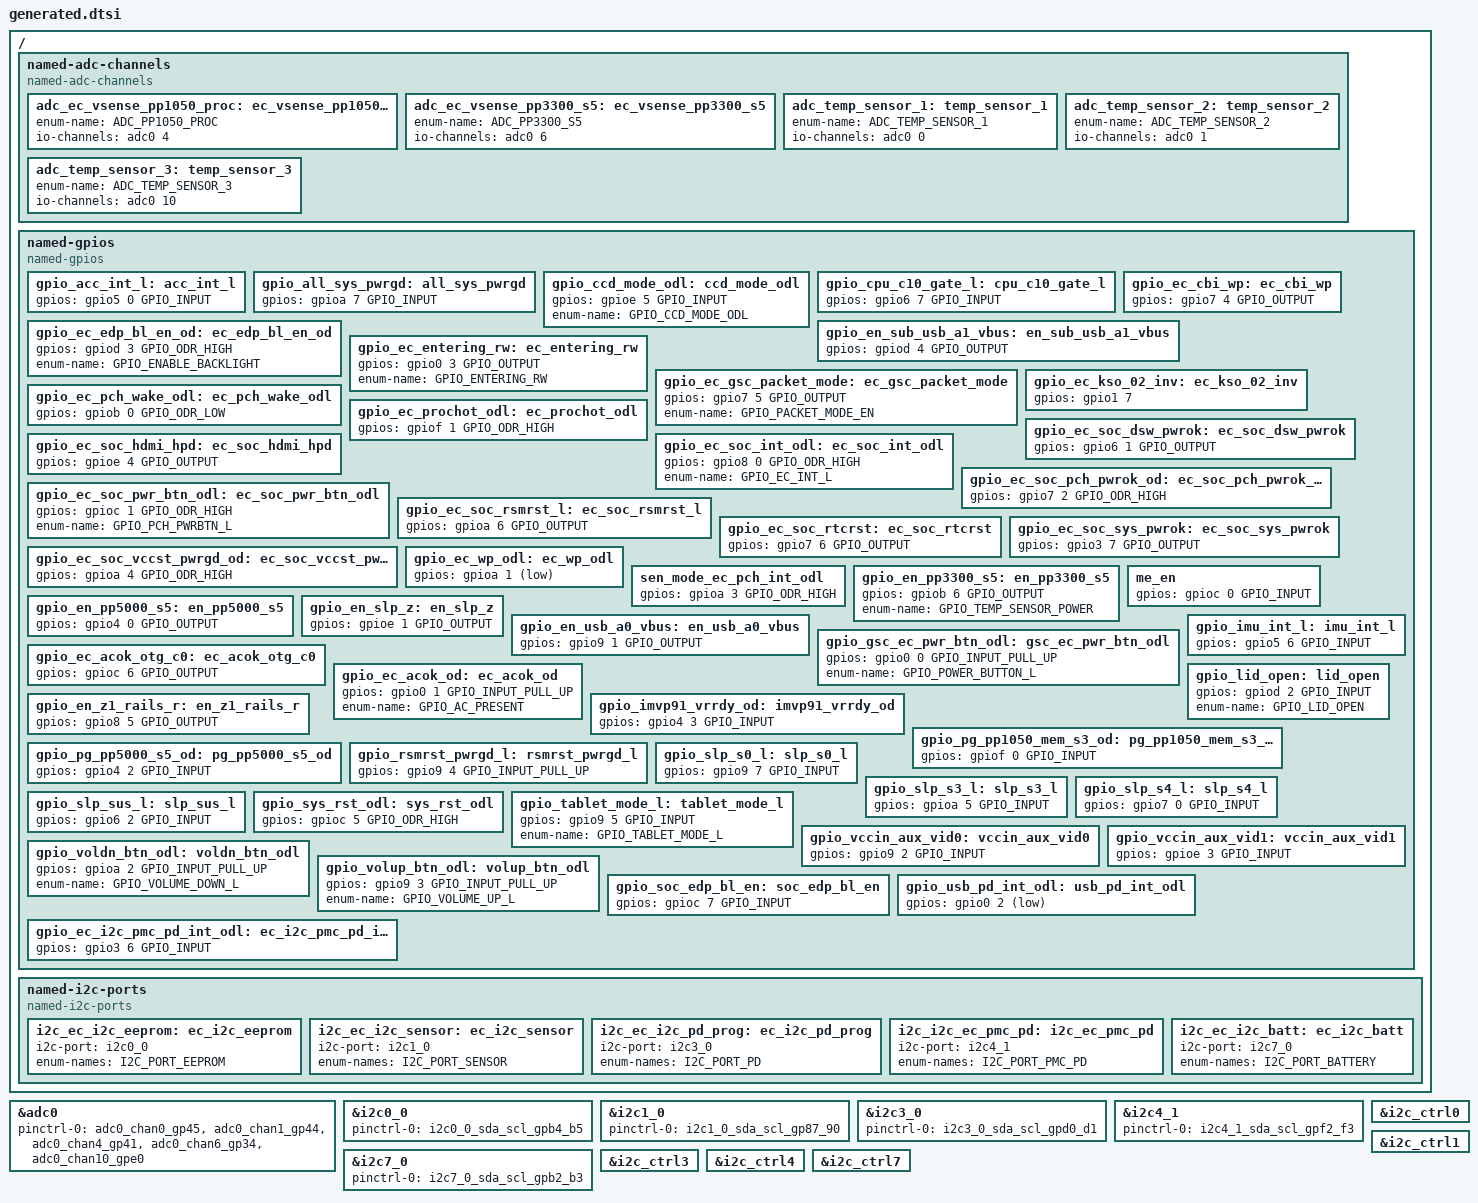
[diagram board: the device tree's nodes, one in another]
/* Copyright 2022 The ChromiumOS Authors
 * Use of this source code is governed by a BSD-style license that can be
 * found in the LICENSE file.
 *
 * This file is auto-generated - do not edit!
 */

/ {

	named-adc-channels {
		compatible = "named-adc-channels";

		adc_ec_vsense_pp1050_proc: ec_vsense_pp1050_proc {
			enum-name = "ADC_PP1050_PROC";
			io-channels = <&adc0 4>;
		};
		adc_ec_vsense_pp3300_s5: ec_vsense_pp3300_s5 {
			enum-name = "ADC_PP3300_S5";
			io-channels = <&adc0 6>;
		};
		adc_temp_sensor_1: temp_sensor_1 {
			enum-name = "ADC_TEMP_SENSOR_1";
			io-channels = <&adc0 0>;
		};
		adc_temp_sensor_2: temp_sensor_2 {
			enum-name = "ADC_TEMP_SENSOR_2";
			io-channels = <&adc0 1>;
		};
		adc_temp_sensor_3: temp_sensor_3 {
			enum-name = "ADC_TEMP_SENSOR_3";
			io-channels = <&adc0 10>;
		};
	};

	named-gpios {
		compatible = "named-gpios";

		gpio_acc_int_l: acc_int_l {
			gpios = <&gpio5 0 GPIO_INPUT>;
		};
		gpio_all_sys_pwrgd: all_sys_pwrgd {
			gpios = <&gpioa 7 GPIO_INPUT>;
		};
		gpio_ccd_mode_odl: ccd_mode_odl {
			gpios = <&gpioe 5 GPIO_INPUT>;
			enum-name = "GPIO_CCD_MODE_ODL";
		};
		gpio_cpu_c10_gate_l: cpu_c10_gate_l {
			gpios = <&gpio6 7 GPIO_INPUT>;
		};
		gpio_ec_cbi_wp: ec_cbi_wp {
			gpios = <&gpio7 4 GPIO_OUTPUT>;
		};
		gpio_ec_edp_bl_en_od: ec_edp_bl_en_od {
			gpios = <&gpiod 3 GPIO_ODR_HIGH>;
			enum-name = "GPIO_ENABLE_BACKLIGHT";
		};
		gpio_en_sub_usb_a1_vbus: en_sub_usb_a1_vbus {
			gpios = <&gpiod 4 GPIO_OUTPUT>;
		};
		gpio_ec_entering_rw: ec_entering_rw {
			/* test point */
			gpios = <&gpio0 3 GPIO_OUTPUT>;
			enum-name = "GPIO_ENTERING_RW";
		};
		gpio_ec_gsc_packet_mode: ec_gsc_packet_mode {
			gpios = <&gpio7 5 GPIO_OUTPUT>;
			enum-name = "GPIO_PACKET_MODE_EN";
		};
		gpio_ec_kso_02_inv: ec_kso_02_inv {
			gpios = <&gpio1 7 (GPIO_OUTPUT | GPIO_ACTIVE_HIGH)>;
		};
		gpio_ec_pch_wake_odl: ec_pch_wake_odl {
			gpios = <&gpiob 0 GPIO_ODR_LOW>;
		};
		gpio_ec_prochot_odl: ec_prochot_odl {
			gpios = <&gpiof 1 GPIO_ODR_HIGH>;
		};
		gpio_ec_soc_dsw_pwrok: ec_soc_dsw_pwrok {
			gpios = <&gpio6 1 GPIO_OUTPUT>;
		};
		gpio_ec_soc_hdmi_hpd: ec_soc_hdmi_hpd {
			gpios = <&gpioe 4 GPIO_OUTPUT>;
		};
		gpio_ec_soc_int_odl: ec_soc_int_odl {
			gpios = <&gpio8 0 GPIO_ODR_HIGH>;
			enum-name = "GPIO_EC_INT_L";
		};
		gpio_ec_soc_pch_pwrok_od: ec_soc_pch_pwrok_od {
			gpios = <&gpio7 2 GPIO_ODR_HIGH>;
		};
		gpio_ec_soc_pwr_btn_odl: ec_soc_pwr_btn_odl {
			gpios = <&gpioc 1 GPIO_ODR_HIGH>;
			enum-name = "GPIO_PCH_PWRBTN_L";
		};
		gpio_ec_soc_rsmrst_l: ec_soc_rsmrst_l {
			gpios = <&gpioa 6 GPIO_OUTPUT>;
		};
		gpio_ec_soc_rtcrst: ec_soc_rtcrst {
			gpios = <&gpio7 6 GPIO_OUTPUT>;
		};
		gpio_ec_soc_sys_pwrok: ec_soc_sys_pwrok {
			gpios = <&gpio3 7 GPIO_OUTPUT>;
		};
		gpio_ec_soc_vccst_pwrgd_od: ec_soc_vccst_pwrgd_od {
			gpios = <&gpioa 4 GPIO_ODR_HIGH>;
		};
		gpio_ec_wp_odl: ec_wp_odl {
			gpios = <&gpioa 1 (GPIO_INPUT | GPIO_ACTIVE_LOW)>;
		};
		sen_mode_ec_pch_int_odl {
			gpios = <&gpioa 3 GPIO_ODR_HIGH>;
		};
		gpio_en_pp3300_s5: en_pp3300_s5 {
			gpios = <&gpiob 6 GPIO_OUTPUT>;
			enum-name = "GPIO_TEMP_SENSOR_POWER";
		};
		me_en {
			/* workaround for b/333336079, reserved */
			gpios = <&gpioc 0 GPIO_INPUT>;
		};
		gpio_en_pp5000_s5: en_pp5000_s5 {
			gpios = <&gpio4 0 GPIO_OUTPUT>;
		};
		gpio_en_slp_z: en_slp_z {
			gpios = <&gpioe 1 GPIO_OUTPUT>;
		};
		gpio_en_usb_a0_vbus: en_usb_a0_vbus {
			gpios = <&gpio9 1 GPIO_OUTPUT>;
		};
		gpio_gsc_ec_pwr_btn_odl: gsc_ec_pwr_btn_odl {
			gpios = <&gpio0 0 GPIO_INPUT_PULL_UP>;
			enum-name = "GPIO_POWER_BUTTON_L";
		};
		gpio_ec_acok_otg_c0: ec_acok_otg_c0 {
			gpios = <&gpioc 6 GPIO_OUTPUT>;
		};
		gpio_imu_int_l: imu_int_l {
			gpios = <&gpio5 6 GPIO_INPUT>;
		};
		gpio_ec_acok_od: ec_acok_od {
			gpios = <&gpio0 1 GPIO_INPUT_PULL_UP>;
			enum-name = "GPIO_AC_PRESENT";
		};
		gpio_imvp91_vrrdy_od: imvp91_vrrdy_od {
			gpios = <&gpio4 3 GPIO_INPUT>;
		};
		gpio_lid_open: lid_open {
			gpios = <&gpiod 2 GPIO_INPUT>;
			enum-name = "GPIO_LID_OPEN";
		};
		gpio_en_z1_rails_r: en_z1_rails_r {
			gpios = <&gpio8 5 GPIO_OUTPUT>;
		};
		gpio_pg_pp1050_mem_s3_od: pg_pp1050_mem_s3_od {
			gpios = <&gpiof 0 GPIO_INPUT>;
		};
		gpio_pg_pp5000_s5_od: pg_pp5000_s5_od {
			gpios = <&gpio4 2 GPIO_INPUT>;
		};
		gpio_rsmrst_pwrgd_l: rsmrst_pwrgd_l {
			gpios = <&gpio9 4 GPIO_INPUT_PULL_UP>;
		};
		gpio_slp_s0_l: slp_s0_l {
			gpios = <&gpio9 7 GPIO_INPUT>;
		};
		gpio_slp_s3_l: slp_s3_l {
			gpios = <&gpioa 5 GPIO_INPUT>;
		};
		gpio_slp_s4_l: slp_s4_l {
			gpios = <&gpio7 0 GPIO_INPUT>;
		};
		gpio_slp_sus_l: slp_sus_l {
			gpios = <&gpio6 2 GPIO_INPUT>;
		};
		gpio_sys_rst_odl: sys_rst_odl {
			gpios = <&gpioc 5 GPIO_ODR_HIGH>;
		};
		gpio_tablet_mode_l: tablet_mode_l {
			gpios = <&gpio9 5 GPIO_INPUT>;
			enum-name = "GPIO_TABLET_MODE_L";
		};
		gpio_vccin_aux_vid0: vccin_aux_vid0 {
			gpios = <&gpio9 2 GPIO_INPUT>;
		};
		gpio_vccin_aux_vid1: vccin_aux_vid1 {
			gpios = <&gpioe 3 GPIO_INPUT>;
		};
		gpio_voldn_btn_odl: voldn_btn_odl {
			gpios = <&gpioa 2 GPIO_INPUT_PULL_UP>;
			enum-name = "GPIO_VOLUME_DOWN_L";
		};
		gpio_volup_btn_odl: volup_btn_odl {
			gpios = <&gpio9 3 GPIO_INPUT_PULL_UP>;
			enum-name = "GPIO_VOLUME_UP_L";
		};
		gpio_soc_edp_bl_en: soc_edp_bl_en {
			gpios = <&gpioc 7 GPIO_INPUT>;
		};
		gpio_usb_pd_int_odl: usb_pd_int_odl {
			gpios = <&gpio0 2 (GPIO_INPUT | GPIO_ACTIVE_LOW)>;
		};
		gpio_ec_i2c_pmc_pd_int_odl: ec_i2c_pmc_pd_int_odl {
			gpios = <&gpio3 6 GPIO_INPUT>;
		};
	};

	named-i2c-ports {
		compatible = "named-i2c-ports";

		i2c_ec_i2c_eeprom: ec_i2c_eeprom {
			i2c-port = <&i2c0_0>;
			enum-names = "I2C_PORT_EEPROM";
		};
		i2c_ec_i2c_sensor: ec_i2c_sensor {
			i2c-port = <&i2c1_0>;
			enum-names = "I2C_PORT_SENSOR";
		};
		i2c_ec_i2c_pd_prog: ec_i2c_pd_prog {
			i2c-port = <&i2c3_0>;
			enum-names = "I2C_PORT_PD";
		};
		i2c_i2c_ec_pmc_pd: i2c_ec_pmc_pd {
			i2c-port = <&i2c4_1>;
			enum-names = "I2C_PORT_PMC_PD";
		};
		i2c_ec_i2c_batt: ec_i2c_batt {
			i2c-port = <&i2c7_0>;
			enum-names = "I2C_PORT_BATTERY";
		};
	};
};

&adc0 {
	status = "okay";
	pinctrl-0 = <&adc0_chan0_gp45
		     &adc0_chan1_gp44
		     &adc0_chan4_gp41
		     &adc0_chan6_gp34
		     &adc0_chan10_gpe0>;
	pinctrl-names = "default";
};


&i2c0_0 {
	status = "okay";
	pinctrl-0 = <&i2c0_0_sda_scl_gpb4_b5>;
	pinctrl-names = "default";
};

&i2c1_0 {
	status = "okay";
	pinctrl-0 = <&i2c1_0_sda_scl_gp87_90>;
	pinctrl-names = "default";
};

&i2c3_0 {
	status = "okay";
	pinctrl-0 = <&i2c3_0_sda_scl_gpd0_d1>;
	pinctrl-names = "default";
};

&i2c4_1 {
	status = "okay";
	pinctrl-0 = <&i2c4_1_sda_scl_gpf2_f3>;
	pinctrl-names = "default";
};

&i2c7_0 {
	status = "okay";
	pinctrl-0 = <&i2c7_0_sda_scl_gpb2_b3>;
	pinctrl-names = "default";
};

&i2c_ctrl0 {
	status = "okay";
};

&i2c_ctrl1 {
	status = "okay";
};

&i2c_ctrl3 {
	status = "okay";
};

&i2c_ctrl4 {
	status = "okay";
};

&i2c_ctrl7 {
	status = "okay";
};
